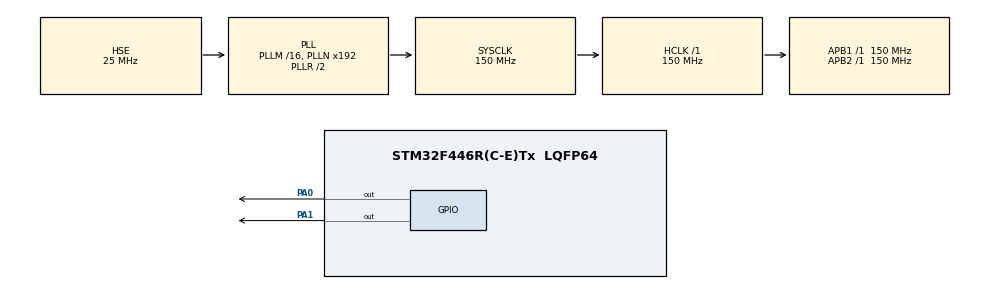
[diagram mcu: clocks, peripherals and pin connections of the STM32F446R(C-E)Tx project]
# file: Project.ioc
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Mcu.Family=STM32F4
Mcu.Name=STM32F446R(C-E)Tx
Mcu.Package=LQFP64
NVIC.PriorityGroup=NVIC_PRIORITYGROUP_4
PA0-WKUP.Signal=GPIO_Output
PA1.Signal=GPIO_Output
PA13.Mode=Serial_Wire
PA13.Signal=SYS_JTMS-SWDIO
PA14.Mode=Serial_Wire
PA14.Signal=SYS_JTCK-SWCLK
PH0-OSC_IN.Mode=HSE-External-Oscillator
PH0-OSC_IN.Signal=RCC_OSC_IN
PH1-OSC_OUT.Mode=HSE-External-Oscillator
PH1-OSC_OUT.Signal=RCC_OSC_OUT
ProjectManager.HeapSize=0x200
ProjectManager.StackSize=0x400
ProjectManager.TargetToolchain=STM32CubeIDE
RCC.AHBFreq_Value=150000000
RCC.APB1Freq_Value=150000000
RCC.APB1TimFreq_Value=150000000
RCC.APB2Freq_Value=150000000
RCC.APB2TimFreq_Value=150000000
RCC.CortexFreq_Value=150000000
RCC.HCLKFreq_Value=150000000
RCC.PLLSourceVirtual=RCC_PLLSOURCE_HSE
RCC.SYSCLKFreq_VALUE=150000000
RCC.SYSCLKSource=RCC_SYSCLKSOURCE_PLLRCLK
RCC.USBFreq_Value=150000000
RCC.VCOOutputFreq_Value=300000000
VP_TIM1_VS_ClockSourceINT.Mode=Internal
board=custom

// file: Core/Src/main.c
/* USER CODE BEGIN Header */
/**
  ******************************************************************************
  * @file           : main.c
  * @brief          : Main program body
  ******************************************************************************
  * @attention
  *
  * Copyright (c) 2023 STMicroelectronics.
  * All rights reserved.
  *
  * This software is licensed under terms that can be found in the LICENSE file
  * in the root directory of this software component.
  * If no LICENSE file comes with this software, it is provided AS-IS.
  *
  ******************************************************************************
  */
/* USER CODE END Header */
#include "main.h"

TIM_HandleTypeDef htim1;

void SystemClock_Config(void);
static void MX_GPIO_Init(void);
static void MX_TIM1_Init(void);

/* USER CODE BEGIN 0 */

void delay (uint16_t us)
{
  __HAL_TIM_SET_COUNTER(&htim1, 0);
  while (__HAL_TIM_GET_COUNTER(&htim1) < us);
}

#define stepsperrev 4096

/* USER CODE END 0 */

void stepper_set_rpm (int rpm)  // Set rpm--> max 13, min 1,,,  went to 14 rev/min
{
	delay(60000000/stepsperrev/rpm);
}

void stepper_half_drive (int step)
{
	switch (step){
		case 0:
			  HAL_GPIO_WritePin(GPIOA, GPIO_PIN_1, GPIO_PIN_SET);   // IN1
			  HAL_GPIO_WritePin(GPIOA, GPIO_PIN_2, GPIO_PIN_RESET);   // IN2
			  HAL_GPIO_WritePin(GPIOA, GPIO_PIN_3, GPIO_PIN_RESET);   // IN3
			  HAL_GPIO_WritePin(GPIOA, GPIO_PIN_4, GPIO_PIN_RESET);   // IN4
			  break;

		case 1:
			  HAL_GPIO_WritePin(GPIOA, GPIO_PIN_1, GPIO_PIN_SET);   // IN1
			  HAL_GPIO_WritePin(GPIOA, GPIO_PIN_2, GPIO_PIN_SET);   // IN2
			  HAL_GPIO_WritePin(GPIOA, GPIO_PIN_3, GPIO_PIN_RESET);   // IN3
			  HAL_GPIO_WritePin(GPIOA, GPIO_PIN_4, GPIO_PIN_RESET);   // IN4
			  break;

		case 2:
			  HAL_GPIO_WritePin(GPIOA, GPIO_PIN_1, GPIO_PIN_RESET);   // IN1
			  HAL_GPIO_WritePin(GPIOA, GPIO_PIN_2, GPIO_PIN_SET);   // IN2
			  HAL_GPIO_WritePin(GPIOA, GPIO_PIN_3, GPIO_PIN_RESET);   // IN3
			  HAL_GPIO_WritePin(GPIOA, GPIO_PIN_4, GPIO_PIN_RESET);   // IN4
			  break;

		case 3:
			  HAL_GPIO_WritePin(GPIOA, GPIO_PIN_1, GPIO_PIN_RESET);   // IN1
			  HAL_GPIO_WritePin(GPIOA, GPIO_PIN_2, GPIO_PIN_SET);   // IN2
			  HAL_GPIO_WritePin(GPIOA, GPIO_PIN_3, GPIO_PIN_SET);   // IN3
			  HAL_GPIO_WritePin(GPIOA, GPIO_PIN_4, GPIO_PIN_RESET);   // IN4
			  break;

		case 4:
			  HAL_GPIO_WritePin(GPIOA, GPIO_PIN_1, GPIO_PIN_RESET);   // IN1
			  HAL_GPIO_WritePin(GPIOA, GPIO_PIN_2, GPIO_PIN_RESET);   // IN2
			  HAL_GPIO_WritePin(GPIOA, GPIO_PIN_3, GPIO_PIN_SET);   // IN3
			  HAL_GPIO_WritePin(GPIOA, GPIO_PIN_4, GPIO_PIN_RESET);   // IN4
			  break;

		case 5:
			  HAL_GPIO_WritePin(GPIOA, GPIO_PIN_1, GPIO_PIN_RESET);   // IN1
			  HAL_GPIO_WritePin(GPIOA, GPIO_PIN_2, GPIO_PIN_RESET);   // IN2
			  HAL_GPIO_WritePin(GPIOA, GPIO_PIN_3, GPIO_PIN_SET);   // IN3
			  HAL_GPIO_WritePin(GPIOA, GPIO_PIN_4, GPIO_PIN_SET);   // IN4
			  break;

		case 6:
			  HAL_GPIO_WritePin(GPIOA, GPIO_PIN_1, GPIO_PIN_RESET);   // IN1
			  HAL_GPIO_WritePin(GPIOA, GPIO_PIN_2, GPIO_PIN_RESET);   // IN2
			  HAL_GPIO_WritePin(GPIOA, GPIO_PIN_3, GPIO_PIN_RESET);   // IN3
			  HAL_GPIO_WritePin(GPIOA, GPIO_PIN_4, GPIO_PIN_SET);   // IN4
			  break;

		case 7:
			  HAL_GPIO_WritePin(GPIOA, GPIO_PIN_1, GPIO_PIN_SET);   // IN1
			  HAL_GPIO_WritePin(GPIOA, GPIO_PIN_2, GPIO_PIN_RESET);   // IN2
			  HAL_GPIO_WritePin(GPIOA, GPIO_PIN_3, GPIO_PIN_RESET);   // IN3
			  HAL_GPIO_WritePin(GPIOA, GPIO_PIN_4, GPIO_PIN_SET);   // IN4
			  break;

		}
}

void stepper_step_angle (float angle, int direction, int rpm)
{
	float anglepersequence = 0.703125;  // 360 = 512 sequences
	int numberofsequences = (int) (angle/anglepersequence);

	for (int seq=0; seq<numberofsequences; seq++)
	{
		if (direction == 0)  // for clockwise
		{
			for (int step=7; step>=0; step--)
			{
				stepper_half_drive(step);
				stepper_set_rpm(rpm);
			}

		}

		else if (direction == 1)  // for anti-clockwise
		{
			for (int step=0; step<8; step++)
			{
				stepper_half_drive(step);
				stepper_set_rpm(rpm);
			}
		}
	}
}
int main(void)
{

  /* MCU Configuration--------------------------------------------------------*/

  /* Reset of all peripherals, Initializes the Flash interface and the Systick. */
  HAL_Init();

  /* Configure the system clock */
  SystemClock_Config();

  /* Initialize all configured peripherals */
  MX_GPIO_Init();
  MX_TIM1_Init();

  /* Infinite loop */
  while (1)
  {

  }
}

void SystemClock_Config(void)
{
  RCC_OscInitTypeDef RCC_OscInitStruct = {0};
  RCC_ClkInitTypeDef RCC_ClkInitStruct = {0};

  /** Configure the main internal regulator output voltage
  */
  __HAL_RCC_PWR_CLK_ENABLE();
  __HAL_PWR_VOLTAGESCALING_CONFIG(PWR_REGULATOR_VOLTAGE_SCALE1);

  /** Initializes the RCC Oscillators according to the specified parameters
  * in the RCC_OscInitTypeDef structure.
  */
  RCC_OscInitStruct.OscillatorType = RCC_OSCILLATORTYPE_HSE;
  RCC_OscInitStruct.HSEState = RCC_HSE_ON;
  RCC_OscInitStruct.PLL.PLLState = RCC_PLL_ON;
  RCC_OscInitStruct.PLL.PLLSource = RCC_PLLSOURCE_HSE;
  RCC_OscInitStruct.PLL.PLLM = 16;
  RCC_OscInitStruct.PLL.PLLN = 192;
  RCC_OscInitStruct.PLL.PLLP = RCC_PLLP_DIV2;
  RCC_OscInitStruct.PLL.PLLQ = 2;
  RCC_OscInitStruct.PLL.PLLR = 2;
  if (HAL_RCC_OscConfig(&RCC_OscInitStruct) != HAL_OK)
  {
    Error_Handler();
  }

  /** Initializes the CPU, AHB and APB buses clocks
  */
  RCC_ClkInitStruct.ClockType = RCC_CLOCKTYPE_HCLK|RCC_CLOCKTYPE_SYSCLK
                              |RCC_CLOCKTYPE_PCLK1|RCC_CLOCKTYPE_PCLK2;
  RCC_ClkInitStruct.SYSCLKSource = RCC_SYSCLKSOURCE_PLLRCLK;
  RCC_ClkInitStruct.AHBCLKDivider = RCC_SYSCLK_DIV1;
  RCC_ClkInitStruct.APB1CLKDivider = RCC_HCLK_DIV1;
  RCC_ClkInitStruct.APB2CLKDivider = RCC_HCLK_DIV1;

  if (HAL_RCC_ClockConfig(&RCC_ClkInitStruct, FLASH_LATENCY_4) != HAL_OK)
  {
    Error_Handler();
  }
}

static void MX_TIM1_Init(void)
{

  TIM_ClockConfigTypeDef sClockSourceConfig = {0};
  TIM_MasterConfigTypeDef sMasterConfig = {0};

  htim1.Instance = TIM1;
  htim1.Init.Prescaler = 0;
  htim1.Init.CounterMode = TIM_COUNTERMODE_UP;
  htim1.Init.Period = 65535;
  htim1.Init.ClockDivision = TIM_CLOCKDIVISION_DIV1;
  htim1.Init.RepetitionCounter = 0;
  htim1.Init.AutoReloadPreload = TIM_AUTORELOAD_PRELOAD_DISABLE;
  if (HAL_TIM_Base_Init(&htim1) != HAL_OK)
  {
    Error_Handler();
  }
  sClockSourceConfig.ClockSource = TIM_CLOCKSOURCE_INTERNAL;
  if (HAL_TIM_ConfigClockSource(&htim1, &sClockSourceConfig) != HAL_OK)
  {
    Error_Handler();
  }
  sMasterConfig.MasterOutputTrigger = TIM_TRGO_RESET;
  sMasterConfig.MasterSlaveMode = TIM_MASTERSLAVEMODE_DISABLE;
  if (HAL_TIMEx_MasterConfigSynchronization(&htim1, &sMasterConfig) != HAL_OK)
  {
    Error_Handler();
  }

}

static void MX_GPIO_Init(void)
{
  GPIO_InitTypeDef GPIO_InitStruct = {0};

  /* GPIO Ports Clock Enable */
  __HAL_RCC_GPIOH_CLK_ENABLE();
  __HAL_RCC_GPIOA_CLK_ENABLE();

  /*Configure GPIO pin Output Level */
  HAL_GPIO_WritePin(GPIOA, GPIO_PIN_0|GPIO_PIN_1, GPIO_PIN_RESET);

  /*Configure GPIO pins : PA0 PA1 */
  GPIO_InitStruct.Pin = GPIO_PIN_0|GPIO_PIN_1;
  GPIO_InitStruct.Mode = GPIO_MODE_OUTPUT_PP;
  GPIO_InitStruct.Pull = GPIO_NOPULL;
  GPIO_InitStruct.Speed = GPIO_SPEED_FREQ_LOW;
  HAL_GPIO_Init(GPIOA, &GPIO_InitStruct);

}

void Error_Handler(void)
{
  __disable_irq();
  while (1)
  {
  }
}
